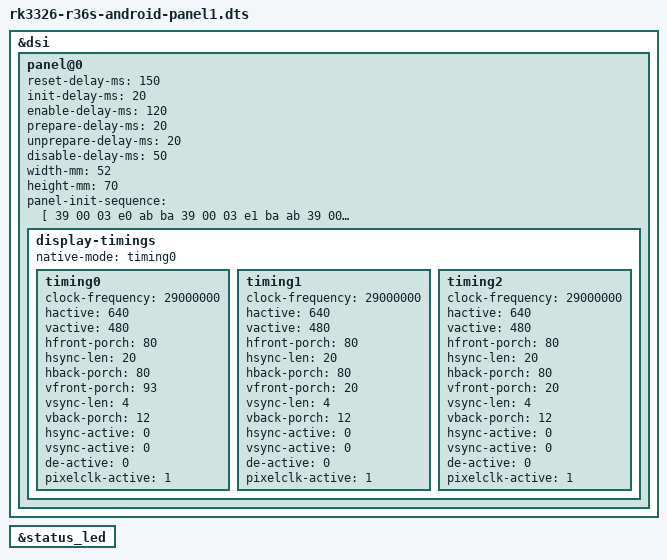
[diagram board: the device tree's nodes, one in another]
// SPDX-License-Identifier: (GPL-2.0+ OR MIT)
/*
 * Copyright (c) 2020 Hardkernel Co., Ltd
 */

/dts-v1/;
#include "rk3326-r36s-android.dtsi"


&dsi {
	panel@0 {
		reset-delay-ms = <150>;
		init-delay-ms = <20>;
		enable-delay-ms = <120>;
		prepare-delay-ms = <20>;
		unprepare-delay-ms = <20>;
		disable-delay-ms = <50>;
		width-mm = <52>;
		height-mm = <70>;
		panel-init-sequence = [
		39 00 03 e0 ab ba 
		39 00 03 e1 ba ab 
		39 00 05 b1 10 01 47 ff 
		39 00 07 b2 0c 08 04 50 50 14 
		39 00 04 b3 56 12 e0 
		39 00 04 b4 33 30 04 
		39 00 08 b6 b0 00 00 10 00 10 00 
		39 00 06 b8 05 12 29 49 48 
		39 00 27 b9 7f 63 52 45 42 34 
		39 24 3e 3d 3c 59 46 4d 3e 3d 30 22 00 7f 63 52 45 42 34 
		39 24 3e 3d 3c 59 46 4d 3e 3d 30 22 00
		39 00 11 c0 32 10 12 34 22 22 22 22 90 04 90 04 0f 00 00 c1 
		39 00 0b c1 12 9f 8e 89 90 04 90 04 54 40 
		39 00 0d c2 77 09 08 89 08 11 22 33 44 87 18 00 
		39 00 17 c3 88 4a 24 24 1e 1f 12 0c 0e 10 04 06 24 24 02 02 02 02 02 02 02 02 
		39 00 17 c4 09 0b 24 24 1e 1f 13 0d 0f 11 05 07 24 24 02 02 02 02 02 02 02 02 
		39 00 03 c6 46 55 
		39 00 07 c8 12 00 31 42 34 16 
		39 00 03 ca 18 43 
		39 00 09 cd 0e 64 64 2c 16 6b 06 b3 
		39 00 05 d2 e3 2b 38 08 
		39 00 0c d4 00 01 00 0e 04 44 08 10 00 00 00 
		39 00 09 e6 80 09 ff ff ff ff ff ff 
		39 00 06 f0 12 03 20 00 ff 
		15 00 02 f3 03 
		05 c8 01 11 
		05 14 01 29
		];

		display-timings {
			native-mode = <&timing0>;

			timing0 {
				clock-frequency = <29000000>;
				hactive = <640>;
				vactive = <480>;
				hfront-porch = <80>;
				hsync-len = <20>;
				hback-porch = <80>;
				vfront-porch = <93>;	/* was 20: 68.5 Hz; 60.04 Hz, same pixel clock */
				vsync-len = <4>;
				vback-porch = <12>;
				hsync-active = <0>;
				vsync-active = <0>;
				de-active = <0>;
				pixelclk-active = <1>;
			};

			timing1 {
				clock-frequency = <29000000>;
				hactive = <640>;
				vactive = <480>;
				hfront-porch = <80>;
				hsync-len = <20>;
				hback-porch = <80>;
				vfront-porch = <20>;
				vsync-len = <4>;
				vback-porch = <12>;
				hsync-active = <0>;
				vsync-active = <0>;
				de-active = <0>;
				pixelclk-active = <1>;
			};

			timing2 {
				clock-frequency = <29000000>;
				hactive = <640>;
				vactive = <480>;
				hfront-porch = <80>;
				hsync-len = <20>;
				hback-porch = <80>;
				vfront-porch = <20>;
				vsync-len = <4>;
				vback-porch = <12>;
				hsync-active = <0>;
				vsync-active = <0>;
				de-active = <0>;
				pixelclk-active = <1>;
			};
		};
	};
};

&status_led {
	status = "okay";
};
